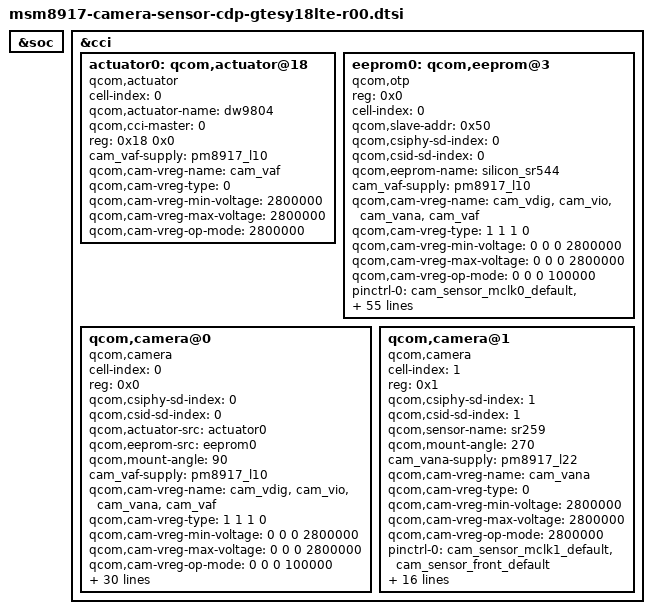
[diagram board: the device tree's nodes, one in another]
/*
 * Copyright (c) 2014, The Linux Foundation. All rights reserved.
 *
 * This program is free software; you can redistribute it and/or modify
 * it under the terms of the GNU General Public License version 2 and
 * only version 2 as published by the Free Software Foundation.
 *
 * This program is distributed in the hope that it will be useful,
 * but WITHOUT ANY WARRANTY; without even the implied warranty of
 * MERCHANTABILITY or FITNESS FOR A PARTICULAR PURPOSE.  See the
 * GNU General Public License for more details.
 */
&soc {
};

&cci {
	
	actuator0: qcom,actuator@18 {
		compatible = "qcom,actuator";
		cell-index = <0>;
		qcom,actuator-name = "dw9804";
		qcom,cci-master = <0>;
		reg = <0x18 0x0>;
		cam_vaf-supply = <&pm8917_l10>;
		qcom,cam-vreg-name = "cam_vaf";
		qcom,cam-vreg-type = <0>;
		qcom,cam-vreg-min-voltage = <2800000>;
		qcom,cam-vreg-max-voltage = <2800000>;
		qcom,cam-vreg-op-mode = <2800000>;
	};	
	eeprom0: qcom,eeprom@3 {
		compatible = "qcom,otp";
		reg = <0x0>;
		cell-index = <0>;
		qcom,slave-addr = <0x50>;
		qcom,csiphy-sd-index = <0>;
		qcom,csid-sd-index = <0>;
		qcom,eeprom-name = "silicon_sr544";
		cam_vaf-supply = <&pm8917_l10>;
		qcom,cam-vreg-name = "cam_vdig", "cam_vio", "cam_vana", "cam_vaf";
		qcom,cam-vreg-type = <1 1 1 0>;
		qcom,cam-vreg-min-voltage = <0 0 0 2800000>;
		qcom,cam-vreg-max-voltage = <0 0 0 2800000>;
		qcom,cam-vreg-op-mode = <0 0 0 100000>;
		pinctrl-names = "cam_default", "cam_suspend";
		pinctrl-0 = <&cam_sensor_mclk0_default   &cam_core_en_default &cam_sensor_rear_default>;
		pinctrl-1 = <&cam_sensor_mclk0_sleep &cam_core_en_sleep &cam_sensor_rear_sleep>;
					gpios = <&tlmm 26 0>,
			<&tlmm 88 0>,
			<&tlmm 39 0>,
			<&tlmm 36 0>,
			<&tlmm 41 0>;
		qcom,gpio-vana = <1>;
		qcom,gpio-vdig = <2>;
		qcom,gpio-reset = <3>;
		qcom,gpio-standby = <4>;
		qcom,gpio-req-tbl-num = <0 1 2 3 4>;
		qcom,gpio-req-tbl-flags = <1 0 0 0 0>;
		qcom,gpio-req-tbl-label = "CAMIF_MCLK",
			"CAM_VANA",
			"CAM_VDIG",
			"CAM_RESET1",
			"CAM_STBY1";
		qcom,sensor-position = <0>;
		qcom,sensor-mode = <0>;
		qcom,cci-master = <0>;
		qcom,cam-power-seq-type = "sensor_gpio", "sensor_vreg", "sensor_gpio", "sensor_gpio",  "sensor_gpio", "sensor_clk", "sensor_gpio", "sensor_gpio", "sensor_i2c_mux";
		qcom,cam-power-seq-val = "sensor_gpio_standby", "cam_vaf", "sensor_gpio_vdig", "sensor_gpio_vana", "sensor_gpio_standby", "sensor_cam_mclk", "sensor_gpio_reset","sensor_gpio_reset","none";
		qcom,cam-power-seq-cfg-val = <0 1 1 1 1 26022000 0 1 0>;
		qcom,cam-power-seq-delay =   <1 2 1 1 1 5 10 3 1>;
		status = "ok";
		clocks = <&clock_gcc clk_mclk0_clk_src>,
			   <&clock_gcc clk_gcc_camss_mclk0_clk>;
		clock-names = "cam_src_clk", "cam_clk";
		qcom,num-blocks = <8>;
		qcom,page0 = <0 0 0 0 0 0>;
		qcom,poll0 = <0 0 0 0 0 0>;
		qcom,mem0 = <0x50 0x00 2 0 1 0>;
		qcom,page1 = <0 0 0 0 0 0>;
		qcom,poll1 = <0 0 0 0 0 0>;
		qcom,mem1 = <0x4 0x5C 2 0 1 0>;
		qcom,page2 = <0 0 0 0 0 0>;
		qcom,poll2 = <0 0 0 0 0 0>;
		qcom,mem2 = <0x70 0x60 2 0 1 0>;
		qcom,page3 = <0 0 0 0 0 0>;
		qcom,poll3 = <0 0 0 0 0 0>;
		qcom,mem3 = <0x4 0xDC 2 0 1 0>;
		qcom,page4 = <0 0 0 0 0 0>;
		qcom,poll4 = <0 0 0 0 0 0>;
		qcom,mem4 = <0x30 0xE0 2 0 1 0>;
		qcom,page5 = <0 0 0 0 0 0>;
		qcom,poll5 = <0 0 0 0 0 0>;
		qcom,mem5 = <0x4 0x11C 2 0 1 0>;
		qcom,page6 = <0 0 0 0 0 0>;
		qcom,poll6 = <0 0 0 0 0 0>;
		qcom,mem6 = <0x710 0x120 2 0 1 0>;
		qcom,page7 = <0 0 0 0 0 0>;
		qcom,poll7 = <0 0 0 0 0 0>;
		qcom,mem7 = <0x4 0x83C 2 0 1 0>;
		qcom,total-size = <0x850>;
	};
	qcom,camera@0 {
		cell-index = <0>;
		compatible = "qcom,camera";
		reg = <0x0>;
		qcom,csiphy-sd-index = <0>;
		qcom,csid-sd-index = <0>;
		qcom,actuator-src = <&actuator0>;
		qcom,eeprom-src = <&eeprom0>;
		qcom,mount-angle = <90>;
		cam_vaf-supply = <&pm8917_l10>;
		qcom,cam-vreg-name = "cam_vdig", "cam_vio", "cam_vana", "cam_vaf";
		qcom,cam-vreg-type = <1 1 1 0>;
		qcom,cam-vreg-min-voltage = <0 0 0 2800000>;
		qcom,cam-vreg-max-voltage = <0 0 0 2800000>;
		qcom,cam-vreg-op-mode = <0 0 0 100000>;
		pinctrl-names = "cam_default", "cam_suspend";
		pinctrl-0 = <&cam_sensor_mclk0_default   &cam_core_en_default &cam_sensor_rear_default>;
		pinctrl-1 = <&cam_sensor_mclk0_sleep &cam_core_en_sleep &cam_sensor_rear_sleep>;
					gpios = <&tlmm 26 0>,
			<&tlmm 88 0>,
			<&tlmm 39 0>,
			<&tlmm 36 0>,
			<&tlmm 41 0>;
		qcom,gpio-vana = <1>;
		qcom,gpio-vdig = <2>;
		qcom,gpio-reset = <3>;
		qcom,gpio-standby = <4>;
		qcom,gpio-req-tbl-num = <0 1 2 3 4>;
		qcom,gpio-req-tbl-flags = <1 0 0 0 0>;
		qcom,gpio-req-tbl-label = "CAMIF_MCLK",
			"CAM_VANA",
			"CAM_VDIG",
			"CAM_RESET1",
			"CAM_STBY1";
		qcom,sensor-position = <0>;
		qcom,sensor-mode = <0>;
		qcom,cci-master = <0>;
		status = "ok";
		clocks = <&clock_gcc clk_mclk0_clk_src>,
			   <&clock_gcc clk_gcc_camss_mclk0_clk>;
		clock-names = "cam_src_clk", "cam_clk";
		qcom,clock-rates = <24000000 0>;
		cam,isp = <0>;                  // 0 : INT , 1 : EXT , 2 : SOC
		cam,cal_memory = <0>;           // 0 : N , 1 : FROM , 2 : EEPROM , 3 : OTP
		cam,read_version = <0>;         // 0 : SYSFS , 1 : CAMON
		cam,core_voltage = <0>;         // 0 : N , 1 : Y
		cam,upgrade = <0>;              // 0 : N , 1 : SYSFS , 2 : CAMON
		cam,fw_write = <0>;             // 0 : N , 1 : OS , 2 : SD , 3 : ALL
		cam,fw_dump = <0>;              // 0 : N , 1 : Y
		cam,companion_chip = <0>;       // 0 : N , 1 : Y
		cam,ois = <0>;                  // 0 : N , 1 : Y
		cam,valid = <1>;                // 0 : N , 1 : Y
	};
	qcom,camera@1 {
		cell-index = <1>;
		compatible = "qcom,camera";
		reg = <0x1>;
		qcom,csiphy-sd-index = <1>;
		qcom,csid-sd-index = <1>;
		qcom,sensor-name = "sr259";
		qcom,mount-angle = <270>;
		cam_vana-supply = <&pm8917_l22>;
		qcom,cam-vreg-name = "cam_vana";
		qcom,cam-vreg-type = <0>;
		qcom,cam-vreg-min-voltage = <2800000>;
		qcom,cam-vreg-max-voltage = <2800000>;
		qcom,cam-vreg-op-mode = <2800000>;
		pinctrl-names = "cam_default", "cam_suspend";
		pinctrl-0 = <&cam_sensor_mclk1_default &cam_sensor_front_default>;
		pinctrl-1 = <&cam_sensor_mclk1_sleep &cam_sensor_front_sleep>;
		gpios = <&tlmm 27 0>,  //VTCAM_MCLK
			  <&tlmm 39 0>,  //CAM_IO_1P8
			  <&tlmm 38 0>,  //VTCAM_RST_N
			  <&tlmm 40 0>;  //VTCAM_STBY
		qcom,gpio-vdig = <1>;
		qcom,gpio-reset = <2>;
		qcom,gpio-standby = <3>;
		qcom,gpio-req-tbl-num = <0 1 2 3>;
		qcom,gpio-req-tbl-flags = <1 0 0 0>;
		qcom,gpio-req-tbl-label = "CAMIF_MCLK",
			"CAM_VDIG",
			"CAM_RESET",
			"CAM_STBY";
		qcom,sensor-position = <1>;
		qcom,sensor-mode = <0>;
		qcom,cci-master = <0>;
		status = "ok";
		clocks = <&clock_gcc clk_mclk1_clk_src>,
			   <&clock_gcc clk_gcc_camss_mclk1_clk>;
		clock-names = "cam_src_clk", "cam_clk";
		qcom,clock-rates = <24000000 0>;
	};		
};


